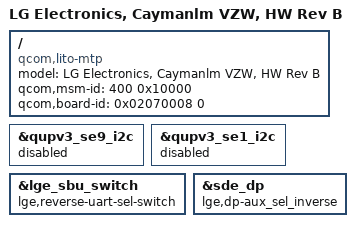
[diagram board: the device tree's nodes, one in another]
/dts-v1/;
/plugin/;

#include <dt-bindings/interrupt-controller/arm-gic.h>
#include "lito-caymanlm_lao_com.dtsi"
#include "lito-caymanlm_vzw-pm.dtsi"
#include "../lito-camera/lito-caymanlm-camera_rev-a.dtsi"
#include "lito-caymanlm_lao_com-fingerprint.dtsi"
#include "lito-caymanlm_lao_com-usb_rev-1.0.dtsi"
#include "lito-caymanlm_lao_com-sound_rev-a.dtsi"
#include "lito-caymanlm_lao_com-touch_rev-1.0.dtsi"

/ {
	model = "LG Electronics, Caymanlm VZW, HW Rev B";
	compatible = "qcom,lito-mtp", "qcom,lito", "qcom,mtp";
	qcom,msm-id = <400 0x10000>;
	qcom,board-id = <0x02070008 0>;
};

&qupv3_se9_i2c {
		status = "disabled";
};

&qupv3_se1_i2c {
	status = "disabled";
};

&lge_sbu_switch {
	lge,reverse-uart-sel-switch;
};

&sde_dp {
	lge,dp-aux_sel_inverse;
};
